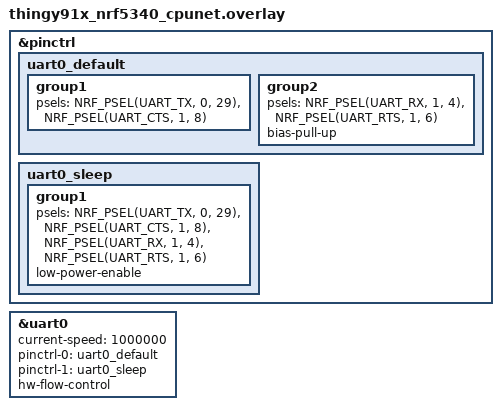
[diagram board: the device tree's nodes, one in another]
/*
 * Copyright (c) 2025 Golioth, Inc.
 * SPDX-License-Identifier: Apache-2.0
 */

&pinctrl {
	uart0_default: uart0_default {
		group1 {
			psels = <NRF_PSEL(UART_TX, 0, 29)>,
			        <NRF_PSEL(UART_CTS, 1, 8)>;
		};
		group2 {
			psels = <NRF_PSEL(UART_RX, 1, 4)>,
			        <NRF_PSEL(UART_RTS, 1, 6)>;
			bias-pull-up;
		};
	};

	uart0_sleep: uart0_sleep {
		group1 {
			psels = <NRF_PSEL(UART_TX, 0, 29)>,
				<NRF_PSEL(UART_CTS, 1, 8)>,
				<NRF_PSEL(UART_RX, 1, 4)>,
				<NRF_PSEL(UART_RTS, 1, 6)>;
			low-power-enable;
		};
	};
};

&uart0_sleep {
	group1 {
		psels = <NRF_PSEL(UART_TX, 0, 29)>,
			<NRF_PSEL(UART_CTS, 1, 8)>,
			<NRF_PSEL(UART_RX, 1, 4)>,
			<NRF_PSEL(UART_RTS, 1, 6)>;
		low-power-enable;
	};
};

&uart0 {
	status = "okay";
	current-speed = <1000000>;
	pinctrl-0 = <&uart0_default>;
	pinctrl-1 = <&uart0_sleep>;
	pinctrl-names = "default", "sleep";
	hw-flow-control;
};
